AUTOSAR XML (schema 4-0-2)
standard types defined: sint16, boolean
package /pkg_tick
  mode declaration group mdg_tick: initial-mode=md_Init
    mode md_Init
    mode md_Run
  sender receiver interface in_Tick_tick
    data count: sw-calibration-access=READ-ONLY, type=dt_sint16
  client server interface in_TickReset_reset
    operation op_reset
      arg count: sw-calibration-access=READ-ONLY, type=dt_sint16, direction=IN
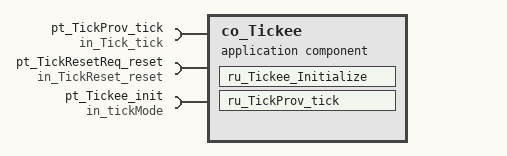
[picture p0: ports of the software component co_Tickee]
  application sw component type co_Tickee
    require port pt_TickProv_tick: required-interface=in_Tick_tick
    require port pt_TickResetReq_reset: required-interface=in_TickReset_reset
    require port pt_Tickee_init: required-interface=in_tickMode
    behavior ib_Tickee: data-type-mapping=DataTMappingSet, supports-multiple-instantiation=true
      exclusive area ea_Tickee
      ar-typed-per-instance-memorys:
        data pm_clamp: type=dt_sint16
      data received event ev_TickProv_tick: start-on-event=ru_TickProv_tick, data=pt_TickProv_tick.count
      swc mode switch event ev_Tickee_Initialize: start-on-event=ru_Tickee_Initialize, activation=ON-ENTRY, mode=pt_Tickee_init.mdgp_tick.md_Init
      runnable ru_Tickee_Initialize: can-enter-exclusive-area=ea_Tickee, can-be-invoked-concurrently=true, symbol=ib_Tickee_ru_Tickee_Initialize
      runnable ru_TickProv_tick: can-enter-exclusive-area=ea_Tickee, can-be-invoked-concurrently=true, symbol=ib_Tickee_ru_TickProv
        data-receive-point-by-arguments:
          access TickProv_tick: accessed-variable=pt_TickProv_tick.count.count
        sync call TickResetReq_reset: operation=pt_TickResetReq_reset.op_reset, timeout=0.5
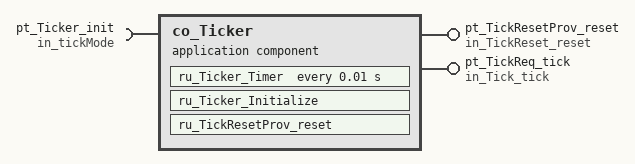
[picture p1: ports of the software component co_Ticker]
  application sw component type co_Ticker
    provide port pt_TickResetProv_reset: provided-interface=in_TickReset_reset
    provide port pt_TickReq_tick: provided-interface=in_Tick_tick
    require port pt_Ticker_init: required-interface=in_tickMode
    behavior ib_Ticker: data-type-mapping=DataTMappingSet, supports-multiple-instantiation=true
      exclusive area ea_Ticker
      ar-typed-per-instance-memorys:
        data pm_count: type=dt_sint16
      timing event ev_Ticker_Timer: start-on-event=ru_Ticker_Timer, period=0.01
      operation invoked event ev_TickResetProv_reset: start-on-event=ru_TickResetProv_reset, operation=pt_TickResetProv_reset.op_reset
      swc mode switch event ev_Ticker_Initialize: start-on-event=ru_Ticker_Initialize, activation=ON-ENTRY, mode=pt_Ticker_init.mdgp_tick.md_Init
      runnable ru_Ticker_Timer: can-enter-exclusive-area=ea_Ticker, can-be-invoked-concurrently=true, symbol=ib_Ticker_ru_TickerTimer
        data-send-points:
          access TickReq_tick: accessed-variable=pt_TickReq_tick.count.count
      runnable ru_Ticker_Initialize: can-enter-exclusive-area=ea_Ticker, can-be-invoked-concurrently=true, symbol=ib_Ticker_ru_Ticker_Initialize
        data-send-points:
          access TickReq_tick: accessed-variable=pt_TickReq_tick.count.count
      runnable ru_TickResetProv_reset: can-enter-exclusive-area=ea_Ticker, can-be-invoked-concurrently=true, symbol=ib_Ticker_ru_TickResetProv_reset
        data-send-points:
          access TickReq_tick: accessed-variable=pt_TickReq_tick.count.count
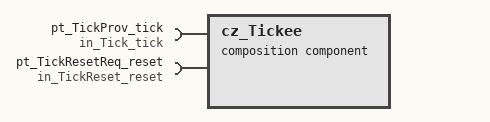
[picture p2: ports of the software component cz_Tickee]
  composition sw component type cz_Tickee
    require port pt_TickProv_tick: required-interface=in_Tick_tick
    require port pt_TickResetReq_reset: required-interface=in_TickReset_reset
    component cp_Tickee: type=co_Tickee
    delegate cp_Tickee.pt_TickProv_tick <-> outer port cz_Tickee/pt_TickProv_tick
    delegate cp_Tickee.pt_TickResetReq_reset <-> outer port cz_Tickee/pt_TickResetReq_reset
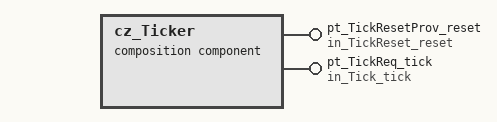
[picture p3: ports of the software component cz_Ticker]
  composition sw component type cz_Ticker
    provide port pt_TickResetProv_reset: provided-interface=in_TickReset_reset
    provide port pt_TickReq_tick: provided-interface=in_Tick_tick
    component cp_Ticker: type=co_Ticker
    delegate cp_Ticker.pt_TickResetProv_reset <-> outer port cz_Ticker/pt_TickResetProv_reset
    delegate cp_Ticker.pt_TickReq_tick <-> outer port cz_Ticker/pt_TickReq_tick
  composition sw component type cz_default
    component cp_cz_Tickee: type=cz_Tickee
    component cp_cz_Ticker: type=cz_Ticker
    connect cp_cz_Ticker.pt_TickReq_tick -> cp_cz_Tickee.pt_TickProv_tick
    connect cp_cz_Ticker.pt_TickResetProv_reset -> cp_cz_Tickee.pt_TickResetReq_reset
  swc implementation im_Tickee: programming-language=C, used-code-generator=BridgePoint xtUML MC3020, vendor-id=31, behavior=ib_Tickee
    code-descriptors:
      code cd_tickee
    resource consumption rc_tickee
      memory section ms_tickee: alignment=10, size=2000
  swc implementation im_Ticker: programming-language=C, used-code-generator=BridgePoint xtUML MC3020, vendor-id=31, behavior=ib_Ticker
    code-descriptors:
      code cd_ticker
    resource consumption rc_ticker
      memory section ms_ticker: alignment=10, size=2000
  app type dt_boolean: category=BOOLEAN, sw-calibration-access=READ-ONLY
  app type dt_sint16: category=VALUE, implementation-data-type=sint16
  data type mapping set DataTMappingSet: data-type-map{application-data-type=dt_sint16, implementation-data-type=sint16}, mode-request-type-map{implementation-data-type=boolean, mode-group=mdg_tick}
  mode switch interface in_tickMode
    mode group mdgp_tick: type=mdg_tick
